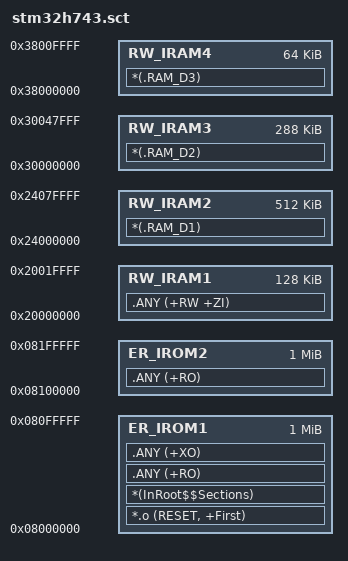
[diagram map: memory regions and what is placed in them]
; *************************************************************
; *** Scatter-Loading Description File generated by uVision ***
; *************************************************************

LR_IROM1 0x08000000 0x00100000  {    ; load region size_region
  ER_IROM1 0x08000000 0x00100000  {  ; load address = execution address
   *.o (RESET, +First)
   *(InRoot$$Sections)
   .ANY (+RO)
   .ANY (+XO)
  }
  
  ; RW data 128KB DTCM
  RW_IRAM1 0x20000000 0x00020000 {
  .ANY (+RW +ZI)
  }
  
  ; RW data 512KB AXI SRAM
  RW_IRAM2 0x24000000 0x00080000 {
  *(.RAM_D1)
  }

  ; RW data 128KB SRAM1(0x30000000) + 128KB SR AM2(0x3002 0000) + 32KB SRAM3(0x30040000)
  RW_IRAM3 0x30000000 0x00048000 {
  *(.RAM_D2)
  }

  ; RW data 64KB SRAM4(0x38000000)
  RW_IRAM4 0x38000000 0x00010000 {
  *(.RAM_D3)
  } 
}

LR_IROM2 0x08100000 0x00100000  {
  ER_IROM2 0x08100000 0x00100000  {  ; load address = execution address
   .ANY (+RO)
  }
}
